# tviic2d6m register map
Vendor: Infineon Technologies; Series: TVIIC2D6M; File version: 1.0
CPU: CM7 r0p1, little endian, MPU, FPU, double-precision FPU, I-cache, D-cache, VTOR, ITCM, DTCM, 3 interrupt priority bits, 16 interrupts
Registers are 32-bit, read-write, reset 0x0 unless marked. A register's access mark holds for its fields unless they carry their own. Offsets are from the block's base; [hi:lo] are bit positions; lines under a group give offsets from that group; {n}, {i} and the like mark numbered series.

## PERI — Peripheral interconnect
Base 0x40000000
0x200 TIMEOUT_CTL reset 0xFFFF — Timeout control
  [15:0] TIMEOUT — This field specifies a number of clock cycles (clk_slow). If an AHB-Lite bus transfer takes more than the specified number of cycles (timeout detection), the bus transfer is terminated with an AHB-Lite bus error and a fault is generated (and possibly recorded in the fault report structure(s)). '0x0000'-'0xfffe': Number of clock cycles. '0xffff': This value is the default/reset value and specifies that no timeout detection is performed: a bus transfer will never be terminated and a fault will never be generated.
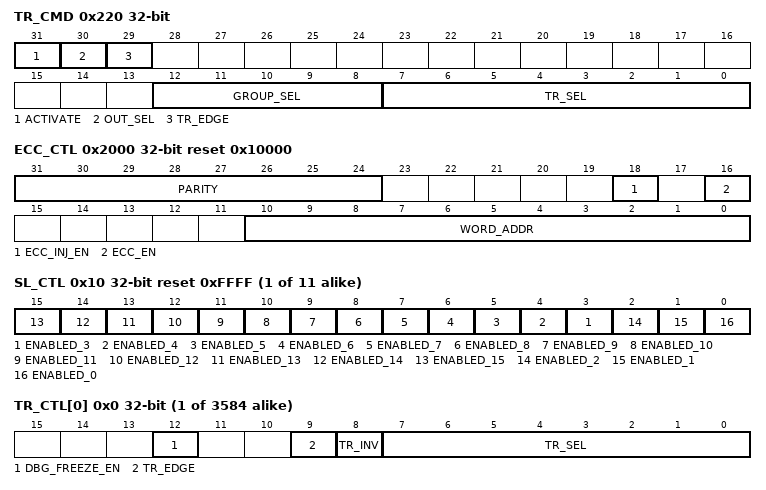
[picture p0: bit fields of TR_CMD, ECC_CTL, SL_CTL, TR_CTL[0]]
0x220 TR_CMD — Trigger command
  [31] ACTIVATE — SW sets this field to '1' to activate (set to '1') a trigger as identified by TR_SEL, TR_EDGE and OUT_SEL. HW sets this field to '0' for edge sensitive triggers AFTER the selected trigger is activated for two clk_peri cycles. Note: when ACTIVATE is '1', SW should not modify the other register fields. SW MUST NOT set ACTIVATE bit to '1' while updating the other register bits simultaneously. At first the SW MUST update the other register bits as needed, and then set ACTIVATE to '1' with a new register write.
  [30] OUT_SEL — Specifies whether trigger activation is for a specific input or output trigger of the trigger multiplexer. Activation of a specific input trigger, will result in activation of all output triggers that have the specific input trigger selected through their TR_OUT_CTL.TR_SEL field. Activation of a specific output trigger, will result in activation of the specified TR_SEL output trigger only. '0': TR_SEL selection and trigger activation is for an input trigger to the trigger multiplexer. '1': TR_SEL selection and trigger activation is for an output trigger from the trigger multiplexer. Note: this field is not used for trigger 1-to-1 groups.
  [29] TR_EDGE — Specifies if the activated trigger is treated as a level sensitive or edge sensitive trigger. '0': level sensitive. The trigger reflects TR_CMD.ACTIVATE. '1': edge sensitive trigger. The trigger is activated for two clk_peri cycles.
  [12:8] GROUP_SEL — Specifies the trigger group: '0'-'15': trigger multiplexer groups. '16'-'31': trigger 1-to-1 groups.
  [7:0] TR_SEL — Specifies the activated trigger when ACTIVATE is '1'. If the specified trigger is not present, the trigger activation has no effect.
0x2000 ECC_CTL reset 0x10000 — ECC control
  [31:24] PARITY — ECC parity to use for ECC error injection at address WORD_ADDR.
  [18] ECC_INJ_EN — Enable error injection for PERI protection structure SRAM. When '1', the parity (PARITY) is used when a write is done to the WORD_ADDR word address of the SRAM.
  [16] ECC_EN — Enable ECC: '0': Disabled (on write ECC parity bits will not be correctly written). '1': Enabled.
  [10:0] WORD_ADDR — Specifies the word address where the parity is injected. - On a 32-bit write access to this SRAM address and when ECC_INJ_EN bit is '1', the parity (PARITY) is injected.
{0x4000+0x40*i} GR[{i}] (i=0..10) group — Peripheral group structure
  0x00 CLOCK_CTL — Clock control
    [15:8] INT8_DIV — Specifies a group clock divider (from the peripheral clock 'clk_peri' to the group clock 'clk_group[3/4/5/...15]'). Integer division by (1+INT8_DIV). Allows for integer divisions in the range [1, 256]. Note that this field is retained. However, the counter that is used to implement the division is not and will be initialized by HW to '0' when transitioning from DeepSleep to Active power mode.
  0x10 SL_CTL reset 0xFFFF — Slave control
    [n] ENABLED_{n} (n=3..15)
    [2] ENABLED_2 — Peripheral group, slave 2 enable. If the slave is disabled, its clock is gated off (constant '0') and its resets are activated. Note: For peripheral group 0 (the peripheral interconnect, PCLK group MMIO registers), this field is a constant '1' (SW: R): the slave can NOT be disabled.
    [1] ENABLED_1 — Peripheral group, slave 1 enable. If the slave is disabled, its clock is gated off (constant '0') and its resets are activated. Note: For peripheral group 0 (the peripheral interconnect, master interface MMIO registers), this field is a constant '1' (SW: R): the slave can NOT be disabled.
    [0] ENABLED_0 — Peripheral group, slave 0 enable. If the slave is disabled, its clock is gated off (constant '0') and its resets are activated. Note: For peripheral group 0 (the peripheral interconnect MMIO registers), this field is a constant '1' (SW: R): the slave can NOT be disabled.
{0x8000+0x400*i} TR_GR[{i}] (i=0..13) group — Trigger group
  {0x0+4j} TR_CTL[{j}] (j=0..255) — Trigger control register
    [12] DBG_FREEZE_EN — Specifies if the output trigger is blocked in debug mode. When set high tr_dbg_freeze will block the output trigger generation.
    [9] TR_EDGE — Specifies if the (inverted) output trigger is treated as a level sensitive or edge sensitive trigger. '0': level sensitive. '1': edge sensitive trigger. The (inverted) output trigger duration needs to be at least 2 cycles on the consumer clock. the(inverted) output trigger is synchronized to the consumer clock and a two cycle pulse is generated on the consumer clock.
    [8] TR_INV — Specifies if the output trigger is inverted.
    [7:0] TR_SEL — Specifies input trigger. This field is typically set during the setup of a chip use case scenario. Changing this field while activated triggers are present on the input triggers may result in unpredictable behavior. Note that input trigger 0 (default value) is typically connected to a constant signal level of '0', and as a result will not cause HW activation of the output trigger.
{0xC000+0x400*i} TR_1TO1_GR[{i}] (i=0..7) group — Trigger 1-to-1 group
  {0x0+4j} TR_CTL[{j}] (j=0..255) — Trigger control register
    [12] DBG_FREEZE_EN — Specifies if the output trigger is blocked in debug mode. When set high tr_dbg_freeze will block the output trigger generation.
    [9] TR_EDGE — Specifies if the (inverted) output trigger is treated as a level sensitive or edge sensitive trigger. '0': level sensitive. '1': edge sensitive trigger. The (inverted) output trigger duration needs to be at least 2 cycles on the consumer clock. the(inverted) output trigger is synchronized to the consumer clock and a two cycle pulse is generated on the consumer clock.
    [8] TR_INV — Specifies if the output trigger is inverted.
    [0] TR_SEL — Specifies input trigger: '0'': constant signal level '0'. '1': input trigger.
